VERSION ""

BS_:

BU_:

BO_ 18 abc: 1 Vector__XXX
 SG_ s2 : 1|7@1+ (1,1) [1|35] "" Vector__XXX
 SG_ s1 : 0|1@1- (1,0) [0|1] "" Vector__XXX

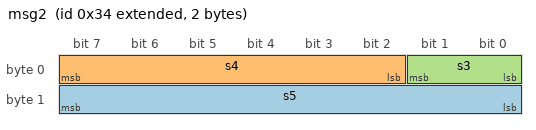
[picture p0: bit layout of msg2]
BO_ 2147483700 msg2: 2 Vector__XXX
 SG_ s5 : 15|8@0+ (1,0) [0|255] "se" Vector__XXX
 SG_ s4 : 2|6@1- (1,0) [-32|31] "" Vector__XXX
 SG_ s3 : 0|2@1- (1,0) [-2|1] "" Vector__XXX

BO_ 69 msg4: 8 Vector__XXX
 SG_ wewe : 17|2@0- (1,0) [-2|1] "" Vector__XXX
 SG_ s1 : 0|2@1- (1,0) [-2|1] "" Vector__XXX

BO_ 2147483749 serewwwww: 4 Vector__XXX
 SG_ s5 : 8|1@1- (1,0) [0|1] "" Vector__XXX
 SG_ s3 : 0|8@1- (2,0) [-256|254] "" Vector__XXX

 VAL_ 2147483700 s5 255 "dfr,35" ;
 VAL_ 2147483700 s4 0 "wew,1" ;
 VAL_ 2147483700 s3 0 "myval,1" ;
